# R7KA8P1AD register map
Vendor: Renesas Electronics Corporation; Series: RA8; File version: 1.10.02
CPU: CM85 r0p2, little endian, MPU, FPU, VTOR, 4 interrupt priority bits, 96 interrupts
Registers are 32-bit, read-write, reset 0x0 unless marked. A register's access mark holds for its fields unless they carry their own. Offsets are from the block's base; [hi:lo] are bit positions; {n}, {i} and the like mark numbered series; 'fields as' and 'values as' point back to an identical list; <NAME> marks a mode.

## VIN0 — VIN0 Register area
Base 0x40347400
Same registers: VIN0_NS 0x50347400
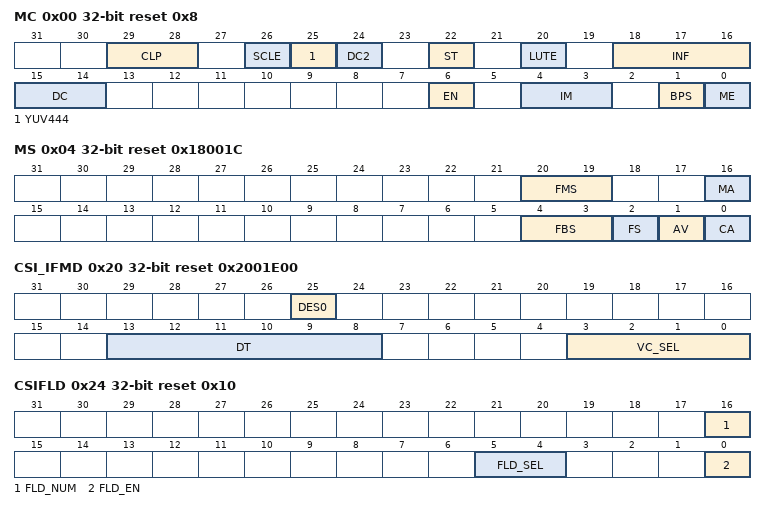
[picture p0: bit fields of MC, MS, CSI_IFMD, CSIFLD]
0x00 MC reset 0x8 — Main Control Register
  [29:28] CLP — Pixel Data Clipping
  [26] SCLE — This bit is used to enable or disable scaling by the UDS.
    0=Disables scaling by the UDS; 1=Enables scaling by the UDS
  [25] YUV444 — YUV444 conversion
    0=The data of CbCr to be interpolated holds the data one pixel before; 1=Generates CbCr data to be interpolated. This register is invalid when the input format is RGB. If the input format is RAW, set 0.
  [24] DC2 — Dithering mode Control 2
    0=Enables dithering in the frame direction; 1=Disables dithering in the frame direction
  [22] ST wo — Initialization control at STartup
    0=Invalid; 1=Perform the initialization procedure. It is prohibited to use it except for the initialization and resumption procedure.
  [20] LUTE — Lookup Table Enable
    0=LUT is not used; 1=LUT is used
  [18:16] INF — Input Interface Format
    0=Setting prohibited; 1=8-bit YCbCr-422; 2=Setting prohibited; 3=10-bit YCbCr-422; 4=8-bit user defined data (RAW8); 5=Setting prohibited; 6=24-bit RGB-888; 7=Setting prohibited
  [15:14] DC — Dithering Mode Control
    0=Dithering with cumulative addition; 1=Ordered dithering 1; 2=Setting prohibited; 3=Ordered dithering 2
  [6] EN — Endian Type
    0=Image data is packed and allocated in little endian; 1=Image data is packed and allocated in big endian
  [4:3] IM — Interlace Mode
    0=Odd-field (field 1) capture mode Handles only odd fields as frames and stores them in external memory; 1=Odd-/even-field capture mode Handles odd and even fields as separate frames and stores them in external memory. This mode is available only in continuous frame capture mode. For progressive input and continuous frame capture mode, set 01b.; 2=Even-field (field 2) capture mode Handles only even fields as frames and stores them in external memory; 3=Setting prohibited
  [1] BPS — Color Space Conversion Bypass Mode
    0=The input YCbCr data is converted into the RGB color space and RGB data is converted into the YCbCr color space; 1=Color space conversion is not performed
  [0] ME — Module Enable
    0=The module operation is stopped; 1=The module operation is enabled
0x04 MS ro reset 0x18001C — Module Status Register
  [20:19] FMS — External Frame Memory buffer Status
    0=The latest valid frame buffer has the base address defined by the memory base 1 register; 1=The latest valid frame buffer has the base address defined by the memory base 2 register; 2=The latest valid frame buffer has the base address defined by the memory base 3 register; 3=There is no valid frame buffer
  [16] MA — External frame Memory capture Active status
    0=Capture to external memory is stopped; 1=Capture to external memory is in operation
  [4:3] FBS — Frame Buffer Status
    values as FMS
  [2] FS — Field Status
    0=The current field is an odd field (field 1); 1=The current field is an even field (field 2)
  [1] AV — Active Video Status
    0=The current field is not in the active video area; 1=The current field is in the active video area
  [0] CA — Video Capture Active Status
    0=Video capture is not operating; 1=Video capture is operating
0x08 FC — Frame Capture Register
  [1] CC — Continuous Frame Capture Mode
    0=The continuous frame capture mode is not set; 1=The continuous frame capture mode is set
0x0C SLPRC — Start Line Pre-Clip Register
  [11:0] SLPRC — Start Line PRe-Clip
0x10 ELPRC — End Line Pre-Clip Register
  [11:0] ELPRC — End Line PRe-Clip
0x14 SPPRC — Start Pixel Pre-Clip Register
  [11:0] SPPRC — Start Pixel Pre-Clip
0x18 EPPRC — End Pixel Pre-Clip Register
  [11:0] EPPRC — End Pixel PRe-Clip
0x20 CSI_IFMD reset 0x2001E00 — CSI2 Interface Mode Register
  [25] DES0 — Data Extension Select
    0=Empty bits in the input data are repeatedly expanded from the highest-order bit; 1=Empty bits will be padded with zeros
  [13:8] DT — Data Type select
    30=YUV422 8-bit; 31=YUV422 10-bit; 36=RGB888; 42=RAW 8-bit
  [3:0] VC_SEL — Virtual Channel SELect
0x24 CSIFLD reset 0x10 — Field Detection Control Register
  [16] FLD_NUM — even FieLD NUMber setting
  [5:4] FLD_SEL — even FieLD DETect SELect
    0=Setting is prohibited; 1=When FLD_NUM matches the field number [0] bit, the field is detected as an even field; 2=Setting is prohibited; 3=Setting is prohibited
  [0] FLD_EN — FieLD detect ENable
    0=Even field detection control disabled; 1=Even field detection control enabled
0x2C IS — Image Stride Register
  [12:0] IS — Image Stride (Setting unit: pixel)
{0x2C+4i} MB{i} (i=1..3) — Memory Base {i} Register
  [31:7] MB{i} — Memory Base Address {i}
0x3C LC ro — Line Count Register
  [11:0] LC — Line Count
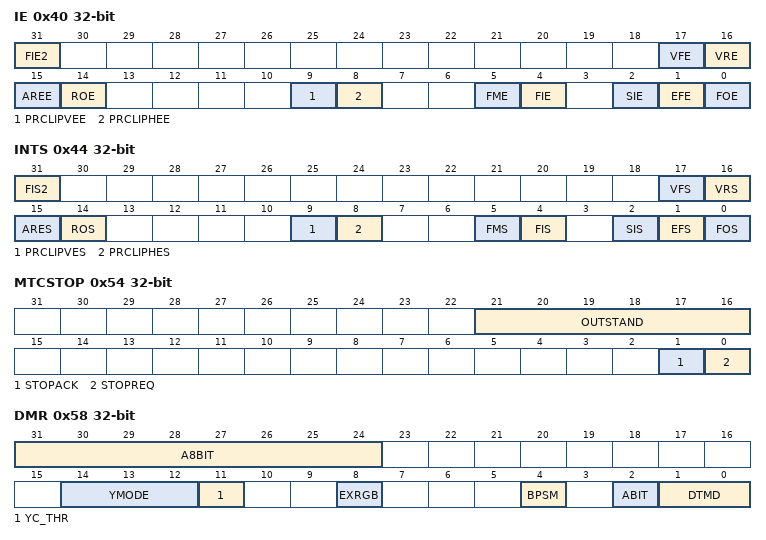
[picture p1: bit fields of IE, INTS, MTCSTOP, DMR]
0x40 IE — Interrupt Enable Register
  [31] FIE2 — Field Interrupt Enable 2
    0=Field interrupts are disabled; 1=Field interrupts are enabled
  [17] VFE — Vsync asserting detect interrupt Enable
    0=VSYNC asserting detect interrupts are disabled; 1=VSYNC asserting detect interrupts are enabled
  [16] VRE — VSYNC Deasserting Detect Interrupt Enable
    0=VSYNC deasserting detect interrupts are disabled; 1=VSYNC deasserting detect interrupts are enabled
  [15] AREE — Axi Resp Error interrupt Enable
    0=AXI Resp error detection interrupt disabled; 1=AXI Resp error detection interrupt enabled
  [14] ROE — Response Overflow interrupt Enable
    0=Response overflow detection interrupt disabled; 1=Response overflow detection interrupt enabled
  [9] PRCLIPVEE — PRCLIPV Error interrupt Enable
    0=PRCLIPV error detection interrupt disabled; 1=PRCLIPV error detection interrupt enabled
  [8] PRCLIPHEE — PRCLIPH Error interrupt Enable
    0=PRCLIPH error detection interrupt disabled; 1=PRCLIPH error detection interrupt enabled
  [5] FME — Frame Memory write completion interrupt Enable
    0=Memory write completion interrupt disabled; 1=Memory write completion interrupt enabled
  [4] FIE — Field Interrupt Enable
    0=Field-switching interrupts are disabled; 1=Field-switching interrupts are enabled
  [2] SIE — Scanline Interrupt Enable
    0=Scanline interrupts are disabled; 1=Scanline interrupts are enabled
  [1] EFE — End of Frame Interrupt Enable
    0=End of frame interrupts are disabled; 1=End of frame interrupts are enabled
  [0] FOE — FIFO Overflow Interrupt Enable
    0=FIFO overflow interrupts are disabled; 1=FIFO overflow interrupts are enabled
0x44 INTS — Interrupt Status Register
  [31] FIS2 — Field Interrupt Status 2
  [17] VFS — VSYNC Asserting Detect Interrupt Status
  [16] VRS — VSYNC Deasserting Detect Interrupt Status
  [15] ARES — Axi Resp Error interrupt Status
  [14] ROS — Response Overflow interrupt Status
  [9] PRCLIPVES — PRCLIPV Error interrupt Status
  [8] PRCLIPHES — PRCLIPH Error interrupt Status
  [5] FMS — Frame Memory write completion interrupt Status
  [4] FIS — Field Interrupt Status
  [2] SIS — Scanline Interrupt Status
  [1] EFS — End of Frame Interrupt Status
  [0] FOS — FIFO Overflow Interrupt Status
0x48 SI — Scanline Interrupt Register
  [11:0] SI — Scanline Interrupt Setting
0x54 MTCSTOP — AXI Transfer Stop Control Register
  [21:16] OUTSTAND ro — OUTSTANDing current number
  [1] STOPACK ro — for axi forced STOP request, ACKnowledgement
  [0] STOPREQ — axi forced STOP REQuest
0x58 DMR — Data Mode Register
  [31:24] A8BIT — Alpha 8
  [14:12] YMODE — YC Data Transfer Mode
    0=Both Y and CbCr data are transferred to memory; 1=Only Y data is transferred to memory as 8-bit data; 2=10-bit Y data and 8-bit CbCr data are transferred to memory; 3=Only Y data is transferred to memory as 10-bit data; {v}=Setting prohibited (v=4..7)
  [11] YC_THR — YC Data Through Mode
    0=Y and CbCr data are transferred to memory in accordance with the setting in the YMODE[2:0] bits; 1=Y and CbCr data are transferred to memory as 10-bit data in accordance with the input format
  [8] EXRGB — Extension RGB Conversion Mode
    0=RGB data extension processing is not performed; 1=Data is extended to 32-bit RGB conversion when DTMD[1:0] is set to 00 or 01 as the data conversion mode
  [4] BPSM — Output Data Byte Swap Mode
    0=Bytes are not swapped in output data; 1=Bytes are swapped in output data
  [2] ABIT — Alpha Bit
    0=The alpha value is set to 0; 1=The alpha value is set to 1
  [1:0] DTMD — Data Conversion Mode
    0=Data is not converted; 1=RGB is converted to ARGB before output; 2=YC is separated before output; 3=Setting prohibited
0x60 UVAOF — UV Address Offset Register
  [31:7] UVAOF — UV Data Address Offset
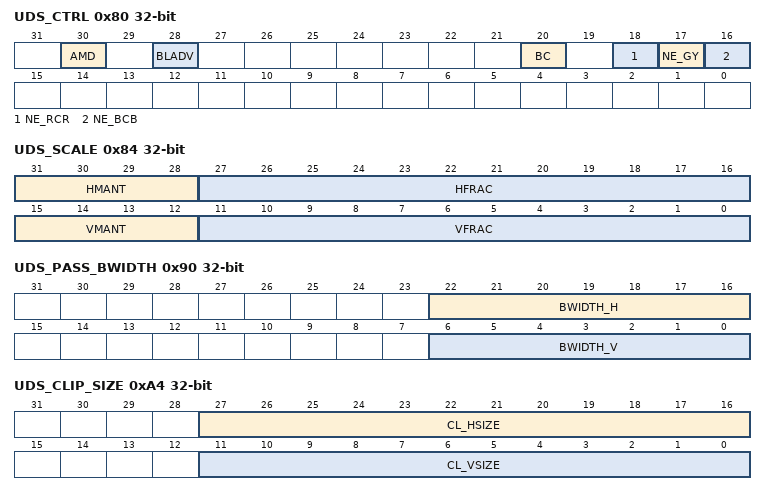
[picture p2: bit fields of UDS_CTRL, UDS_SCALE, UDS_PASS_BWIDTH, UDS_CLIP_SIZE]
0x80 UDS_CTRL — Scaling Control Registers
  [30] AMD — Advanced MoDe: Pixel Count at Scale-Up
    0=Pixel count after scale-up is 1 + < (n - 1) × scale-up factor>; 1=Pixel count after scale-up is <n × scale-up factor>
  [28] BLADV — BiLinear or nearest neighbor interpolation characteristic ADVanced mode
  [20] BC — Pixel Component Interpolation Method at Scale-Up/Down
    0=Bilinear or nearest neighbor interpolation method is used; 1=Interpolation method equivalent to 4 to 17 taps in accordance with the scaling factor is used (multi-tap mode)
  [18] NE_RCR — R/Cr Interpolation Method When Bilinear/Nearest Neighbor Interpolation is Selected
    0=Bilinear method; 1=Nearest neighbor method
  [17] NE_GY — G/Y Interpolation Method When Bilinear/Nearest Neighbor Interpolation is Selected
    0=Bilinear method; 1=Nearest neighbor method
  [16] NE_BCB — B/Cb Interpolation Method When Bilinear/Nearest Neighbor Interpolation is Selected
    0=Bilinear method; 1=Nearest neighbor method
0x84 UDS_SCALE — Scaling Factor Registers
  [31:28] HMANT — Multiplier (Integral Part) of Horizontal Scaling Factor
  [27:16] HFRAC — Multiplier (Fractional Part) of Horizontal Scaling Factor
  [15:12] VMANT — Multiplier (Integral Part) of Vertical Scaling Factor
  [11:0] VFRAC — Multiplier (Fractional Part) of Vertical Scaling Factor
0x90 UDS_PASS_BWIDTH — Passband Registers
  [22:16] BWIDTH_H — Horizontal Signal Passband at Image Scale-Up/Down
  [6:0] BWIDTH_V — Vertical Signal Passband at Image Scale-Up/Down
0xA4 UDS_CLIP_SIZE — UDS Output Size Clipping Registers
  [27:16] CL_HSIZE — Clipping Size of Horizontal Pixel Count after Scale-Up/-Down
  [11:0] CL_VSIZE — Clipping Size of Vertical Pixel Count after Scale-Up/-Down
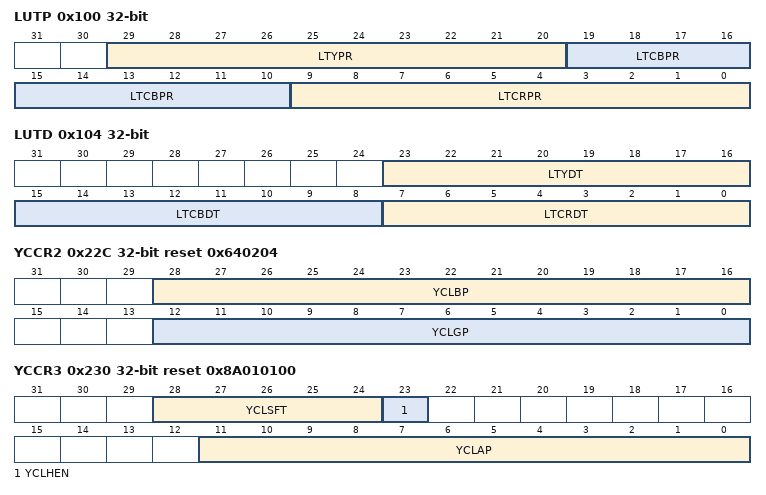
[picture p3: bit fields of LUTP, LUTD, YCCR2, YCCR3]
0x100 LUTP — Lookup Table Pointer Register
  [29:20] LTYPR — Lookup Table Y Pointer
  [19:10] LTCBPR — Lookup Table Cb Pointer
  [9:0] LTCRPR — Lookup Table Cr Pointer
0x104 LUTD (reset mask 0xFF000000) — Lookup Table Data Register
  [23:16] LTYDT — Lookup Table Y Data
  [15:8] LTCBDT — Lookup Table Cb Data
  [7:0] LTCRDT — Lookup Table Cr Data
0x228 YCCR1 reset 0x107 — RGB to Y Calculation Setting Register 1
  [12:0] YCLRP — R Multiplication Coefficient for Y Calculation
0x22C YCCR2 reset 0x640204 — RGB to Y Calculation Setting Register 2
  [28:16] YCLBP — B Multiplication Coefficient for Y Calculation
  [12:0] YCLGP — G Multiplication Coefficient for Y Calculation
0x230 YCCR3 reset 0x8A010100 — RGB to Y Calculation Setting Register 3
  [28:24] YCLSFT — Y Calculation Shift Down Volume
  [23] YCLHEN — Y Calculation Shift Down Result Round-Off Enable
    0=Round down to down shift process; 1=Round-off to down shift process is enabled
  [11:0] YCLAP — Y Calculation Data Normalized Additional Value
0x234 CBCCR1 reset 0x1F68 — RGB to Cb Calculation Setting Register 1
  [12:0] CBCLRP — R Multiplication Coefficient for Cb Calculation
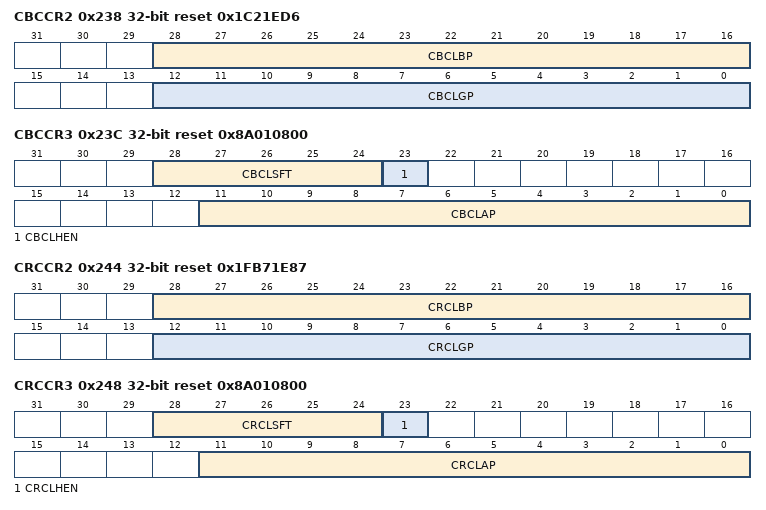
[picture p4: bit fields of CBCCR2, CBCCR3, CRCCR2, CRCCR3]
0x238 CBCCR2 reset 0x1C21ED6 — RGB to Cb Calculation Setting Register 2
  [28:16] CBCLBP — B Multiplication Coefficient for Cb Calculation
  [12:0] CBCLGP — G Multiplication Coefficient for Cb Calculation
0x23C CBCCR3 reset 0x8A010800 — RGB to Cb Calculation Setting Register 3
  [28:24] CBCLSFT — Cb Calculation Shift Down Volume
  [23] CBCLHEN — Cb Calculation Shift Down Result Round-Off Enable
    values as YCCR3.YCLHEN
  [11:0] CBCLAP — Cb Calculation Data Normalized Additional Value
0x240 CRCCR1 reset 0x1C2 — RGB to Cr Calculation Setting Register 1
  [12:0] CRCLRP — R Multiplication Coefficient for Cr Calculation
0x244 CRCCR2 reset 0x1FB71E87 — RGB to Cr Calculation Setting Register 2
  [28:16] CRCLBP — B Multiplication Coefficient for Cr Calculation
  [12:0] CRCLGP — G Multiplication Coefficient for Cr Calculation
0x248 CRCCR3 reset 0x8A010800 — RGB to Cr Calculation Setting Register 3
  [28:24] CRCLSFT — Cr Calculation Shift Down Volume
  [23] CRCLHEN — Cr Calculation Shift Down Result Round-Off Enable
    values as YCCR3.YCLHEN
  [11:0] CRCLAP — Cr Calculation Data Normalized Additional Value
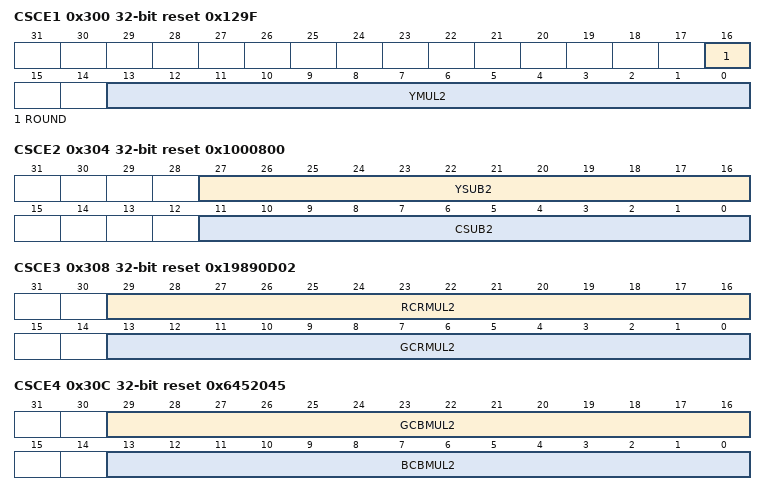
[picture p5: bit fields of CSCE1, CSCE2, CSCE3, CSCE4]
0x300 CSCE1 reset 0x129F — YC to RGB Calculation Setting Extension Register 1
  [16] ROUND — ROUND off enable
    0=Round down; 1=Round off
  [13:0] YMUL2 — Y Multiplication Coefficient 2 for RGB Calculation
0x304 CSCE2 reset 0x1000800 — YC to RGB Calculation Setting Extension Register 2
  [27:16] YSUB2 — Y Subtraction Coefficient 2 for RGB Calculation
  [11:0] CSUB2 — CbCr Subtraction Coefficient 2 for RGB Calculation
0x308 CSCE3 reset 0x19890D02 — YC to RGB Calculation Setting Extension Register 3
  [29:16] RCRMUL2 — Cr Multiplication Coefficient 2 for R Calculation
  [13:0] GCRMUL2 — Cr Multiplication Coefficient 2 for G Calculation
0x30C CSCE4 reset 0x6452045 — YC to RGB Calculation Setting Extension Register 4
  [29:16] GCBMUL2 — Cb Multiplication Coefficient 2 for G Calculation
  [13:0] BCBMUL2 — Cb Multiplication Coefficient 2 for B Calculation
